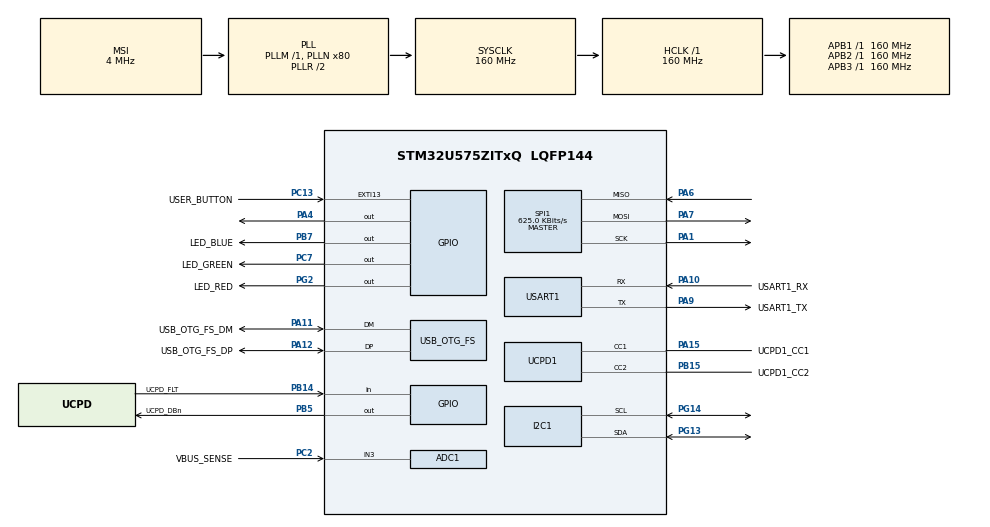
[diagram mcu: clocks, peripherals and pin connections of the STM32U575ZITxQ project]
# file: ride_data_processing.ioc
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ADC1.NbrOfConversion=1
ADC1.Resolution=ADC_RESOLUTION_14B
ADC1.master=1
CORTEX_M33_NS.userName=CORTEX_M33
I2C1.Timing=0x30909DEC
Mcu.Family=STM32U5
Mcu.Name=STM32U575ZITxQ
Mcu.Package=LQFP144
NVIC.OTG_FS_IRQn=true\:0\:0\:false\:false\:true\:true\:true\:true
NVIC.PriorityGroup=NVIC_PRIORITYGROUP_3
PA1.Mode=Full_Duplex_Master
PA1.Signal=SPI1_SCK
PA10.GPIO_Label=USART1_RX
PA10.GPIO_PuPd=GPIO_PULLDOWN
PA10.GPIO_Speed=GPIO_SPEED_FREQ_VERY_HIGH
PA10.Mode=Asynchronous
PA10.Signal=USART1_RX
PA11.GPIO_Label=USB_OTG_FS_DM
PA11.GPIO_Speed=GPIO_SPEED_FREQ_VERY_HIGH
PA11.Mode=Host_Only
PA11.Signal=USB_OTG_FS_DM
PA12.GPIO_Label=USB_OTG_FS_DP
PA12.GPIO_Speed=GPIO_SPEED_FREQ_VERY_HIGH
PA12.Mode=Host_Only
PA12.Signal=USB_OTG_FS_DP
PA13\ (JTMS/SWDIO).Mode=Trace_Asynchronous_SW
PA13\ (JTMS/SWDIO).Signal=DEBUG_JTMS-SWDIO
PA14\ (JTCK/SWCLK).Mode=Trace_Asynchronous_SW
PA14\ (JTCK/SWCLK).Signal=DEBUG_JTCK-SWCLK
PA15\ (JTDI).GPIO_Label=UCPD1_CC1
PA15\ (JTDI).Mode=Sink_AllSignals
PA15\ (JTDI).Signal=UCPD1_CC1
PA4.Signal=GPIO_Output
PA6.Mode=Full_Duplex_Master
PA6.Signal=SPI1_MISO
PA7.Mode=Full_Duplex_Master
PA7.Signal=SPI1_MOSI
PA9.GPIO_Label=USART1_TX
PA9.GPIO_PuPd=GPIO_PULLDOWN
PA9.GPIO_Speed=GPIO_SPEED_FREQ_VERY_HIGH
PA9.Mode=Asynchronous
PA9.Signal=USART1_TX
PB14.GPIO_Label=UCPD_FLT
PB14.Signal=GPIO_Input
PB15.GPIO_Label=UCPD1_CC2
PB15.Mode=Sink_AllSignals
PB15.Signal=UCPD1_CC2
PB3\ (JTDO/TRACESWO).Mode=Trace_Asynchronous_SW
PB3\ (JTDO/TRACESWO).Signal=DEBUG_JTDO-SWO
PB5.GPIO_Label=UCPD_DBn
PB5.Signal=GPIO_Output
PB7.GPIO_Label=LED_BLUE
PB7.GPIO_ModeDefaultOutputPP=GPIO_MODE_OUTPUT_PP
PB7.GPIO_PuPd=GPIO_PULLUP
PB7.GPIO_Speed=GPIO_SPEED_FREQ_HIGH
PB7.Signal=GPIO_Output
PC13.GPIO_Label=USER_BUTTON
PC13.GPIO_ModeDefaultEXTI=GPIO_MODE_IT_FALLING
PC13.Signal=GPXTI13
PC14-OSC32_IN\ (PC14).Mode=LSE-External-Oscillator
PC14-OSC32_IN\ (PC14).Signal=RCC_OSC32_IN
PC15-OSC32_OUT\ (PC15).Mode=LSE-External-Oscillator
PC15-OSC32_OUT\ (PC15).Signal=RCC_OSC32_OUT
PC2.GPIO_Label=VBUS_SENSE
PC2.Mode=IN3-Single-Ended
PC2.Signal=ADC1_IN3
PC7.GPIO_Label=LED_GREEN
PC7.GPIO_PuPd=GPIO_PULLUP
PC7.GPIO_Speed=GPIO_SPEED_FREQ_HIGH
PC7.Signal=GPIO_Output
PG13.Mode=I2C
PG13.Signal=I2C1_SDA
PG14.Mode=I2C
PG14.Signal=I2C1_SCL
PG2.GPIO_Label=LED_RED
PG2.GPIO_ModeDefaultOutputPP=GPIO_MODE_OUTPUT_PP
PG2.GPIO_PuPd=GPIO_PULLUP
PG2.GPIO_Speed=GPIO_SPEED_FREQ_HIGH
PG2.Signal=GPIO_Output
PWR.PowerMode=PWR_SMPS_SUPPLY
ProjectManager.HeapSize=0x200
ProjectManager.StackSize=0x400
ProjectManager.TargetToolchain=STM32CubeIDE
RCC.ADCFreq_Value=16000000
RCC.AHBFreq_Value=160000000
RCC.APB1Freq_Value=160000000
RCC.APB1TimFreq_Value=160000000
RCC.APB2Freq_Value=160000000
RCC.APB2TimFreq_Value=160000000
RCC.APB3Freq_Value=160000000
RCC.CortexFreq_Value=160000000
RCC.DACCLockSelectionVirtual=RCC_DAC1CLKSOURCE_LSI
RCC.EPOD_VALUE=4000000
RCC.HCLKFreq_Value=160000000
RCC.HSE_VALUE=16000000
RCC.HSI48_VALUE=48000000
RCC.HSI_VALUE=16000000
RCC.LSIDIV_VALUE=32000
RCC.MSI_VALUE=4000000
RCC.PLLN=80
RCC.SYSCLKFreq_VALUE=160000000
RCC.SYSCLKSource=RCC_SYSCLKSOURCE_PLLCLK
RCC.USBFreq_Value=48000000
RCC.VCOOutputFreq_Value=320000000
SPI1.BaudRatePrescaler=SPI_BAUDRATEPRESCALER_256
SPI1.CalculateBaudRate=625.0 KBits/s
SPI1.DataSize=SPI_DATASIZE_8BIT
SPI1.Direction=SPI_DIRECTION_2LINES
SPI1.Mode=SPI_MODE_MASTER
SPI1.NSSPMode=SPI_NSS_PULSE_DISABLE
SPI1.VirtualType=VM_MASTER
USART1.VirtualMode-Asynchronous=VM_ASYNC
USB_OTG_FS.VirtualMode=Host_Only
USB_OTG_FS.phy_itface=HCD_PHY_EMBEDDED
VP_ICACHE_VS_ENABLE_ICACHE_MEMORY.Mode=Memoryregions
VP_ICACHE_VS_ICACHE.Mode=DirectMappedCache
VP_IWDG_VS_IWDG.Mode=IWDG_Activate
VP_LPBAMQUEUE_VS_QUEUE.Mode=QUEUEMODE
VP_LPBAM_VS_SIG1.Mode=SmartRun
VP_LPBAM_VS_SIG4.Mode=LPDMA1
VP_MEMORYMAP_VS_MEMORYMAP.Mode=CurAppReg
VP_OCTOSPI1_VS_octo.Mode=octo_mode
VP_PWR_VS_DBSignals.Mode=DisableDeadBatterySignals
VP_PWR_VS_LPOM.Mode=PowerOptimisation
VP_PWR_VS_SECSignals.Mode=Security/Privilege
VP_PWR_Vdda.Mode=isolationVdda
VP_RTC_VS_RTC_Activate.Mode=RTC_Enabled
board=NUCLEO-U575ZI-Q

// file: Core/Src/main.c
/* USER CODE BEGIN Header */
/**
  ******************************************************************************
  * @file           : main.c
  * @brief          : Main program body
  ******************************************************************************
  * @attention
  *
  * Copyright (c) 2024 STMicroelectronics.
  * All rights reserved.
  *
  * This software is licensed under terms that can be found in the LICENSE file
  * in the root directory of this software component.
  * If no LICENSE file comes with this software, it is provided AS-IS.
  *
  ******************************************************************************
  */
/* USER CODE END Header */
#include "main.h"

ADC_HandleTypeDef hadc1;

I2C_HandleTypeDef hi2c1;

IWDG_HandleTypeDef hiwdg;

OSPI_HandleTypeDef hospi1;

RTC_HandleTypeDef hrtc;

SPI_HandleTypeDef hspi1;

UART_HandleTypeDef huart1;

HCD_HandleTypeDef hhcd_USB_OTG_FS;

void SystemClock_Config(void);
static void SystemPower_Config(void);
static void MX_GPIO_Init(void);
static void MX_ADC1_Init(void);
static void MX_ICACHE_Init(void);
static void MX_UCPD1_Init(void);
static void MX_USART1_UART_Init(void);
static void MX_USB_OTG_FS_HCD_Init(void);
static void MX_SPI1_Init(void);
static void MX_IWDG_Init(void);
static void MX_I2C1_Init(void);
static void MX_OCTOSPI1_Init(void);
static void MX_RTC_Init(void);

/* USER CODE BEGIN 0 */
uint8_t tx_buff[]={"1,2,3,4,5,6,7,8,9"};
/* USER CODE END 0 */

int main(void)
{

  /* MCU Configuration--------------------------------------------------------*/

  /* Reset of all peripherals, Initializes the Flash interface and the Systick. */
  HAL_Init();

  /* Configure the system clock */
  SystemClock_Config();

  /* Configure the System Power */
  SystemPower_Config();

  /* Initialize all configured peripherals */
  MX_GPIO_Init();
  MX_ADC1_Init();
  MX_ICACHE_Init();
  MX_UCPD1_Init();
  MX_USART1_UART_Init();
  MX_USB_OTG_FS_HCD_Init();
  MX_SPI1_Init();
  MX_IWDG_Init();
  MX_I2C1_Init();
  MX_OCTOSPI1_Init();
  MX_RTC_Init();

  /* Infinite loop */
  while (1)
  {

    /* USER CODE BEGIN 3 */
	  HAL_UART_Transmit(&huart1, tx_buff, 20, 1000);
	  HAL_Delay(10000);
  }
  /* USER CODE END 3 */
}

void SystemClock_Config(void)
{
  RCC_OscInitTypeDef RCC_OscInitStruct = {0};
  RCC_ClkInitTypeDef RCC_ClkInitStruct = {0};

  /** Configure the main internal regulator output voltage
  */
  if (HAL_PWREx_ControlVoltageScaling(PWR_REGULATOR_VOLTAGE_SCALE1) != HAL_OK)
  {
    Error_Handler();
  }

  /** Initializes the CPU, AHB and APB buses clocks
  */
  RCC_OscInitStruct.OscillatorType = RCC_OSCILLATORTYPE_HSI48|RCC_OSCILLATORTYPE_HSI
                              |RCC_OSCILLATORTYPE_LSI|RCC_OSCILLATORTYPE_MSI;
  RCC_OscInitStruct.HSIState = RCC_HSI_ON;
  RCC_OscInitStruct.HSI48State = RCC_HSI48_ON;
  RCC_OscInitStruct.HSICalibrationValue = RCC_HSICALIBRATION_DEFAULT;
  RCC_OscInitStruct.LSIState = RCC_LSI_ON;
  RCC_OscInitStruct.MSIState = RCC_MSI_ON;
  RCC_OscInitStruct.MSICalibrationValue = RCC_MSICALIBRATION_DEFAULT;
  RCC_OscInitStruct.MSIClockRange = RCC_MSIRANGE_4;
  RCC_OscInitStruct.LSIDiv = RCC_LSI_DIV1;
  RCC_OscInitStruct.PLL.PLLState = RCC_PLL_ON;
  RCC_OscInitStruct.PLL.PLLSource = RCC_PLLSOURCE_MSI;
  RCC_OscInitStruct.PLL.PLLMBOOST = RCC_PLLMBOOST_DIV1;
  RCC_OscInitStruct.PLL.PLLM = 1;
  RCC_OscInitStruct.PLL.PLLN = 80;
  RCC_OscInitStruct.PLL.PLLP = 2;
  RCC_OscInitStruct.PLL.PLLQ = 2;
  RCC_OscInitStruct.PLL.PLLR = 2;
  RCC_OscInitStruct.PLL.PLLRGE = RCC_PLLVCIRANGE_0;
  RCC_OscInitStruct.PLL.PLLFRACN = 0;
  if (HAL_RCC_OscConfig(&RCC_OscInitStruct) != HAL_OK)
  {
    Error_Handler();
  }

  /** Initializes the CPU, AHB and APB buses clocks
  */
  RCC_ClkInitStruct.ClockType = RCC_CLOCKTYPE_HCLK|RCC_CLOCKTYPE_SYSCLK
                              |RCC_CLOCKTYPE_PCLK1|RCC_CLOCKTYPE_PCLK2
                              |RCC_CLOCKTYPE_PCLK3;
  RCC_ClkInitStruct.SYSCLKSource = RCC_SYSCLKSOURCE_PLLCLK;
  RCC_ClkInitStruct.AHBCLKDivider = RCC_SYSCLK_DIV1;
  RCC_ClkInitStruct.APB1CLKDivider = RCC_HCLK_DIV1;
  RCC_ClkInitStruct.APB2CLKDivider = RCC_HCLK_DIV1;
  RCC_ClkInitStruct.APB3CLKDivider = RCC_HCLK_DIV1;

  if (HAL_RCC_ClockConfig(&RCC_ClkInitStruct, FLASH_LATENCY_4) != HAL_OK)
  {
    Error_Handler();
  }
}

/**
  * @brief Power Configuration
  * @retval None
  */
static void SystemPower_Config(void)
{
  HAL_PWREx_EnableVddIO2();

  /*
   * Switch to SMPS regulator instead of LDO
   */
  if (HAL_PWREx_ConfigSupply(PWR_SMPS_SUPPLY) != HAL_OK)
  {
    Error_Handler();
  }
}

static void MX_ADC1_Init(void)
{

  /** Common config
  */
  hadc1.Instance = ADC1;
  hadc1.Init.ClockPrescaler = ADC_CLOCK_ASYNC_DIV1;
  hadc1.Init.Resolution = ADC_RESOLUTION_14B;
  hadc1.Init.GainCompensation = 0;
  hadc1.Init.ScanConvMode = ADC_SCAN_DISABLE;
  hadc1.Init.EOCSelection = ADC_EOC_SINGLE_CONV;
  hadc1.Init.LowPowerAutoWait = DISABLE;
  hadc1.Init.ContinuousConvMode = DISABLE;
  hadc1.Init.NbrOfConversion = 1;
  hadc1.Init.DiscontinuousConvMode = DISABLE;
  hadc1.Init.DMAContinuousRequests = DISABLE;
  hadc1.Init.TriggerFrequencyMode = ADC_TRIGGER_FREQ_HIGH;
  hadc1.Init.Overrun = ADC_OVR_DATA_PRESERVED;
  hadc1.Init.LeftBitShift = ADC_LEFTBITSHIFT_NONE;
  hadc1.Init.ConversionDataManagement = ADC_CONVERSIONDATA_DR;
  hadc1.Init.OversamplingMode = DISABLE;
  if (HAL_ADC_Init(&hadc1) != HAL_OK)
  {
    Error_Handler();
  }

}

static void MX_I2C1_Init(void)
{

  hi2c1.Instance = I2C1;
  hi2c1.Init.Timing = 0x30909DEC;
  hi2c1.Init.OwnAddress1 = 0;
  hi2c1.Init.AddressingMode = I2C_ADDRESSINGMODE_7BIT;
  hi2c1.Init.DualAddressMode = I2C_DUALADDRESS_DISABLE;
  hi2c1.Init.OwnAddress2 = 0;
  hi2c1.Init.OwnAddress2Masks = I2C_OA2_NOMASK;
  hi2c1.Init.GeneralCallMode = I2C_GENERALCALL_DISABLE;
  hi2c1.Init.NoStretchMode = I2C_NOSTRETCH_DISABLE;
  if (HAL_I2C_Init(&hi2c1) != HAL_OK)
  {
    Error_Handler();
  }

  /** Configure Analogue filter
  */
  if (HAL_I2CEx_ConfigAnalogFilter(&hi2c1, I2C_ANALOGFILTER_ENABLE) != HAL_OK)
  {
    Error_Handler();
  }

  /** Configure Digital filter
  */
  if (HAL_I2CEx_ConfigDigitalFilter(&hi2c1, 0) != HAL_OK)
  {
    Error_Handler();
  }

}

static void MX_ICACHE_Init(void)
{

  /** Enable instruction cache in 1-way (direct mapped cache)
  */
  if (HAL_ICACHE_ConfigAssociativityMode(ICACHE_1WAY) != HAL_OK)
  {
    Error_Handler();
  }
  if (HAL_ICACHE_Enable() != HAL_OK)
  {
    Error_Handler();
  }

}

static void MX_IWDG_Init(void)
{

  hiwdg.Instance = IWDG;
  hiwdg.Init.Prescaler = IWDG_PRESCALER_4;
  hiwdg.Init.Window = 4095;
  hiwdg.Init.Reload = 4095;
  hiwdg.Init.EWI = 0;
  if (HAL_IWDG_Init(&hiwdg) != HAL_OK)
  {
    Error_Handler();
  }

}

static void MX_OCTOSPI1_Init(void)
{

  HAL_OSPI_DLYB_CfgTypeDef HAL_OSPI_DLYB_Cfg_Struct = {0};

  /* OCTOSPI1 parameter configuration*/
  hospi1.Instance = OCTOSPI1;
  hospi1.Init.FifoThreshold = 1;
  hospi1.Init.DualQuad = HAL_OSPI_DUALQUAD_DISABLE;
  hospi1.Init.MemoryType = HAL_OSPI_MEMTYPE_MICRON;
  hospi1.Init.DeviceSize = 32;
  hospi1.Init.ChipSelectHighTime = 1;
  hospi1.Init.FreeRunningClock = HAL_OSPI_FREERUNCLK_DISABLE;
  hospi1.Init.ClockMode = HAL_OSPI_CLOCK_MODE_0;
  hospi1.Init.WrapSize = HAL_OSPI_WRAP_NOT_SUPPORTED;
  hospi1.Init.ClockPrescaler = 1;
  hospi1.Init.SampleShifting = HAL_OSPI_SAMPLE_SHIFTING_NONE;
  hospi1.Init.DelayHoldQuarterCycle = HAL_OSPI_DHQC_DISABLE;
  hospi1.Init.ChipSelectBoundary = 0;
  hospi1.Init.DelayBlockBypass = HAL_OSPI_DELAY_BLOCK_BYPASSED;
  hospi1.Init.MaxTran = 0;
  hospi1.Init.Refresh = 0;
  if (HAL_OSPI_Init(&hospi1) != HAL_OK)
  {
    Error_Handler();
  }
  HAL_OSPI_DLYB_Cfg_Struct.Units = 0;
  HAL_OSPI_DLYB_Cfg_Struct.PhaseSel = 0;
  if (HAL_OSPI_DLYB_SetConfig(&hospi1, &HAL_OSPI_DLYB_Cfg_Struct) != HAL_OK)
  {
    Error_Handler();
  }

}

static void MX_RTC_Init(void)
{

  RTC_PrivilegeStateTypeDef privilegeState = {0};

  /** Initialize RTC Only
  */
  hrtc.Instance = RTC;
  hrtc.Init.HourFormat = RTC_HOURFORMAT_24;
  hrtc.Init.AsynchPrediv = 127;
  hrtc.Init.SynchPrediv = 255;
  hrtc.Init.OutPut = RTC_OUTPUT_DISABLE;
  hrtc.Init.OutPutRemap = RTC_OUTPUT_REMAP_NONE;
  hrtc.Init.OutPutPolarity = RTC_OUTPUT_POLARITY_HIGH;
  hrtc.Init.OutPutType = RTC_OUTPUT_TYPE_OPENDRAIN;
  hrtc.Init.OutPutPullUp = RTC_OUTPUT_PULLUP_NONE;
  hrtc.Init.BinMode = RTC_BINARY_NONE;
  if (HAL_RTC_Init(&hrtc) != HAL_OK)
  {
    Error_Handler();
  }
  privilegeState.rtcPrivilegeFull = RTC_PRIVILEGE_FULL_NO;
  privilegeState.backupRegisterPrivZone = RTC_PRIVILEGE_BKUP_ZONE_NONE;
  privilegeState.backupRegisterStartZone2 = RTC_BKP_DR0;
  privilegeState.backupRegisterStartZone3 = RTC_BKP_DR0;
  if (HAL_RTCEx_PrivilegeModeSet(&hrtc, &privilegeState) != HAL_OK)
  {
    Error_Handler();
  }

}

static void MX_SPI1_Init(void)
{

  SPI_AutonomousModeConfTypeDef HAL_SPI_AutonomousMode_Cfg_Struct = {0};

  /* SPI1 parameter configuration*/
  hspi1.Instance = SPI1;
  hspi1.Init.Mode = SPI_MODE_MASTER;
  hspi1.Init.Direction = SPI_DIRECTION_2LINES;
  hspi1.Init.DataSize = SPI_DATASIZE_8BIT;
  hspi1.Init.CLKPolarity = SPI_POLARITY_LOW;
  hspi1.Init.CLKPhase = SPI_PHASE_1EDGE;
  hspi1.Init.NSS = SPI_NSS_SOFT;
  hspi1.Init.BaudRatePrescaler = SPI_BAUDRATEPRESCALER_256;
  hspi1.Init.FirstBit = SPI_FIRSTBIT_MSB;
  hspi1.Init.TIMode = SPI_TIMODE_DISABLE;
  hspi1.Init.CRCCalculation = SPI_CRCCALCULATION_DISABLE;
  hspi1.Init.CRCPolynomial = 0x7;
  hspi1.Init.NSSPMode = SPI_NSS_PULSE_DISABLE;
  hspi1.Init.NSSPolarity = SPI_NSS_POLARITY_LOW;
  hspi1.Init.FifoThreshold = SPI_FIFO_THRESHOLD_01DATA;
  hspi1.Init.MasterSSIdleness = SPI_MASTER_SS_IDLENESS_00CYCLE;
  hspi1.Init.MasterInterDataIdleness = SPI_MASTER_INTERDATA_IDLENESS_00CYCLE;
  hspi1.Init.MasterReceiverAutoSusp = SPI_MASTER_RX_AUTOSUSP_DISABLE;
  hspi1.Init.MasterKeepIOState = SPI_MASTER_KEEP_IO_STATE_DISABLE;
  hspi1.Init.IOSwap = SPI_IO_SWAP_DISABLE;
  hspi1.Init.ReadyMasterManagement = SPI_RDY_MASTER_MANAGEMENT_INTERNALLY;
  hspi1.Init.ReadyPolarity = SPI_RDY_POLARITY_HIGH;
  if (HAL_SPI_Init(&hspi1) != HAL_OK)
  {
    Error_Handler();
  }
  HAL_SPI_AutonomousMode_Cfg_Struct.TriggerState = SPI_AUTO_MODE_DISABLE;
  HAL_SPI_AutonomousMode_Cfg_Struct.TriggerSelection = SPI_GRP1_GPDMA_CH0_TCF_TRG;
  HAL_SPI_AutonomousMode_Cfg_Struct.TriggerPolarity = SPI_TRIG_POLARITY_RISING;
  if (HAL_SPIEx_SetConfigAutonomousMode(&hspi1, &HAL_SPI_AutonomousMode_Cfg_Struct) != HAL_OK)
  {
    Error_Handler();
  }

}

static void MX_UCPD1_Init(void)
{

  LL_GPIO_InitTypeDef GPIO_InitStruct = {0};

  /* Peripheral clock enable */
  LL_APB1_GRP2_EnableClock(LL_APB1_GRP2_PERIPH_UCPD1);

  LL_AHB2_GRP1_EnableClock(LL_AHB2_GRP1_PERIPH_GPIOB);
  LL_AHB2_GRP1_EnableClock(LL_AHB2_GRP1_PERIPH_GPIOA);
  /**UCPD1 GPIO Configuration
  PB15   ------> UCPD1_CC2
  PA15 (JTDI)   ------> UCPD1_CC1
  */
  GPIO_InitStruct.Pin = LL_GPIO_PIN_15;
  GPIO_InitStruct.Mode = LL_GPIO_MODE_ANALOG;
  GPIO_InitStruct.Pull = LL_GPIO_PULL_NO;
  LL_GPIO_Init(GPIOB, &GPIO_InitStruct);

  GPIO_InitStruct.Pin = LL_GPIO_PIN_15;
  GPIO_InitStruct.Mode = LL_GPIO_MODE_ANALOG;
  GPIO_InitStruct.Pull = LL_GPIO_PULL_NO;
  LL_GPIO_Init(GPIOA, &GPIO_InitStruct);

}

static void MX_USART1_UART_Init(void)
{

  huart1.Instance = USART1;
  huart1.Init.BaudRate = 115200;
  huart1.Init.WordLength = UART_WORDLENGTH_8B;
  huart1.Init.StopBits = UART_STOPBITS_1;
  huart1.Init.Parity = UART_PARITY_NONE;
  huart1.Init.Mode = UART_MODE_TX_RX;
  huart1.Init.HwFlowCtl = UART_HWCONTROL_NONE;
  huart1.Init.OverSampling = UART_OVERSAMPLING_16;
  huart1.Init.OneBitSampling = UART_ONE_BIT_SAMPLE_DISABLE;
  huart1.Init.ClockPrescaler = UART_PRESCALER_DIV1;
  huart1.AdvancedInit.AdvFeatureInit = UART_ADVFEATURE_NO_INIT;
  if (HAL_UART_Init(&huart1) != HAL_OK)
  {
    Error_Handler();
  }
  if (HAL_UARTEx_SetTxFifoThreshold(&huart1, UART_TXFIFO_THRESHOLD_1_8) != HAL_OK)
  {
    Error_Handler();
  }
  if (HAL_UARTEx_SetRxFifoThreshold(&huart1, UART_RXFIFO_THRESHOLD_1_8) != HAL_OK)
  {
    Error_Handler();
  }
  if (HAL_UARTEx_DisableFifoMode(&huart1) != HAL_OK)
  {
    Error_Handler();
  }

}

static void MX_USB_OTG_FS_HCD_Init(void)
{

  hhcd_USB_OTG_FS.Instance = USB_OTG_FS;
  hhcd_USB_OTG_FS.Init.Host_channels = 12;
  hhcd_USB_OTG_FS.Init.speed = HCD_SPEED_FULL;
  hhcd_USB_OTG_FS.Init.dma_enable = DISABLE;
  hhcd_USB_OTG_FS.Init.phy_itface = HCD_PHY_EMBEDDED;
  hhcd_USB_OTG_FS.Init.Sof_enable = DISABLE;
  hhcd_USB_OTG_FS.Init.vbus_sensing_enable = DISABLE;
  if (HAL_HCD_Init(&hhcd_USB_OTG_FS) != HAL_OK)
  {
    Error_Handler();
  }

}

static void MX_GPIO_Init(void)
{
  GPIO_InitTypeDef GPIO_InitStruct = {0};

  /* GPIO Ports Clock Enable */
  __HAL_RCC_GPIOC_CLK_ENABLE();
  __HAL_RCC_GPIOA_CLK_ENABLE();
  __HAL_RCC_GPIOB_CLK_ENABLE();
  __HAL_RCC_GPIOG_CLK_ENABLE();

  /*Configure GPIO pin Output Level */
  HAL_GPIO_WritePin(GPIOA, GPIO_PIN_4, GPIO_PIN_RESET);

  /*Configure GPIO pin Output Level */
  HAL_GPIO_WritePin(LED_RED_GPIO_Port, LED_RED_Pin, GPIO_PIN_RESET);

  /*Configure GPIO pin Output Level */
  HAL_GPIO_WritePin(LED_GREEN_GPIO_Port, LED_GREEN_Pin, GPIO_PIN_RESET);

  /*Configure GPIO pin Output Level */
  HAL_GPIO_WritePin(GPIOB, UCPD_DBn_Pin|LED_BLUE_Pin, GPIO_PIN_RESET);

  /*Configure GPIO pin : USER_BUTTON_Pin */
  GPIO_InitStruct.Pin = USER_BUTTON_Pin;
  GPIO_InitStruct.Mode = GPIO_MODE_IT_FALLING;
  GPIO_InitStruct.Pull = GPIO_NOPULL;
  HAL_GPIO_Init(USER_BUTTON_GPIO_Port, &GPIO_InitStruct);

  /*Configure GPIO pin : PA4 */
  GPIO_InitStruct.Pin = GPIO_PIN_4;
  GPIO_InitStruct.Mode = GPIO_MODE_OUTPUT_PP;
  GPIO_InitStruct.Pull = GPIO_NOPULL;
  GPIO_InitStruct.Speed = GPIO_SPEED_FREQ_LOW;
  HAL_GPIO_Init(GPIOA, &GPIO_InitStruct);

  /*Configure GPIO pin : UCPD_FLT_Pin */
  GPIO_InitStruct.Pin = UCPD_FLT_Pin;
  GPIO_InitStruct.Mode = GPIO_MODE_INPUT;
  GPIO_InitStruct.Pull = GPIO_NOPULL;
  HAL_GPIO_Init(UCPD_FLT_GPIO_Port, &GPIO_InitStruct);

  /*Configure GPIO pin : LED_RED_Pin */
  GPIO_InitStruct.Pin = LED_RED_Pin;
  GPIO_InitStruct.Mode = GPIO_MODE_OUTPUT_PP;
  GPIO_InitStruct.Pull = GPIO_PULLUP;
  GPIO_InitStruct.Speed = GPIO_SPEED_FREQ_HIGH;
  HAL_GPIO_Init(LED_RED_GPIO_Port, &GPIO_InitStruct);

  /*Configure GPIO pin : LED_GREEN_Pin */
  GPIO_InitStruct.Pin = LED_GREEN_Pin;
  GPIO_InitStruct.Mode = GPIO_MODE_OUTPUT_PP;
  GPIO_InitStruct.Pull = GPIO_PULLUP;
  GPIO_InitStruct.Speed = GPIO_SPEED_FREQ_HIGH;
  HAL_GPIO_Init(LED_GREEN_GPIO_Port, &GPIO_InitStruct);

  /*Configure GPIO pin : UCPD_DBn_Pin */
  GPIO_InitStruct.Pin = UCPD_DBn_Pin;
  GPIO_InitStruct.Mode = GPIO_MODE_OUTPUT_PP;
  GPIO_InitStruct.Pull = GPIO_NOPULL;
  GPIO_InitStruct.Speed = GPIO_SPEED_FREQ_LOW;
  HAL_GPIO_Init(UCPD_DBn_GPIO_Port, &GPIO_InitStruct);

  /*Configure GPIO pin : LED_BLUE_Pin */
  GPIO_InitStruct.Pin = LED_BLUE_Pin;
  GPIO_InitStruct.Mode = GPIO_MODE_OUTPUT_PP;
  GPIO_InitStruct.Pull = GPIO_PULLUP;
  GPIO_InitStruct.Speed = GPIO_SPEED_FREQ_HIGH;
  HAL_GPIO_Init(LED_BLUE_GPIO_Port, &GPIO_InitStruct);

}

void Error_Handler(void)
{
  __disable_irq();
  while (1)
  {
  }
}
